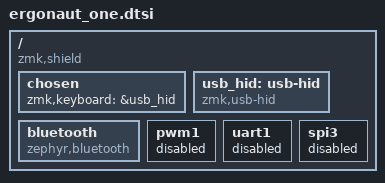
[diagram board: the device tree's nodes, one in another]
/ {
    compatible = "zmk,shield";

    chosen {
        zmk,keyboard = &usb_hid; // Указывает, что это HID устройство
    };

    usb_hid: usb-hid {
        compatible = "zmk,usb-hid";
    };

    bluetooth: bluetooth {
        status = "okay";
        compatible = "zephyr,bluetooth";
    };

    pwm1: pwm1 {
        status = "disabled";
    };

    uart1: uart1 {
        status = "disabled";
    };

    spi3: spi3 {
        status = "disabled";
    };
};
